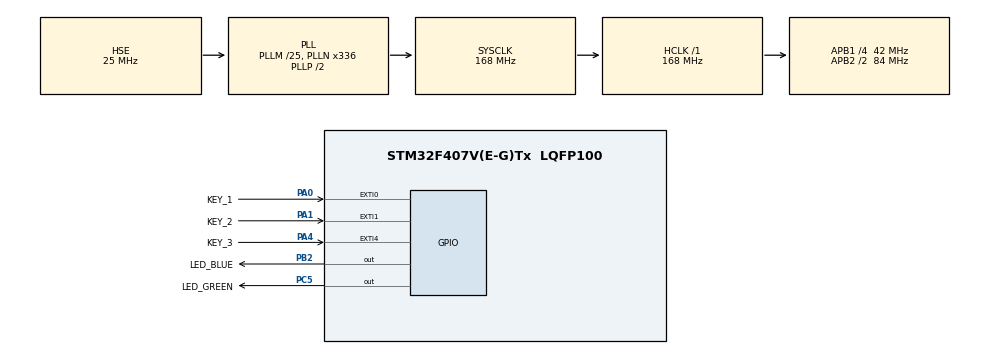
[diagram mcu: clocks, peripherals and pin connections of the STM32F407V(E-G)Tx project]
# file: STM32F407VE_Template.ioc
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Mcu.Family=STM32F4
Mcu.Name=STM32F407V(E-G)Tx
Mcu.Package=LQFP100
NVIC.EXTI0_IRQn=true\:0\:0\:false\:false\:true\:true\:true\:true
NVIC.EXTI1_IRQn=true\:0\:0\:false\:false\:true\:true\:true\:true
NVIC.EXTI4_IRQn=true\:0\:0\:false\:false\:true\:true\:true\:true
NVIC.PriorityGroup=NVIC_PRIORITYGROUP_4
PA0-WKUP.GPIO_Label=KEY_1
PA0-WKUP.GPIO_ModeDefaultEXTI=GPIO_MODE_IT_RISING
PA0-WKUP.GPIO_PuPd=GPIO_PULLDOWN
PA0-WKUP.Signal=GPXTI0
PA1.GPIO_Label=KEY_2
PA1.GPIO_ModeDefaultEXTI=GPIO_MODE_IT_FALLING
PA1.GPIO_PuPd=GPIO_PULLUP
PA1.Signal=GPXTI1
PA13.Mode=Serial_Wire
PA13.Signal=SYS_JTMS-SWDIO
PA14.Mode=Serial_Wire
PA14.Signal=SYS_JTCK-SWCLK
PA4.GPIO_Label=KEY_3
PA4.GPIO_ModeDefaultEXTI=GPIO_MODE_IT_FALLING
PA4.GPIO_PuPd=GPIO_PULLUP
PA4.Signal=GPXTI4
PB2.GPIO_Label=LED_BLUE
PB2.GPIO_PuPd=GPIO_PULLDOWN
PB2.Signal=GPIO_Output
PC5.GPIO_Label=LED_GREEN
PC5.GPIO_PuPd=GPIO_PULLDOWN
PC5.Signal=GPIO_Output
PH0-OSC_IN.Mode=HSE-External-Oscillator
PH0-OSC_IN.Signal=RCC_OSC_IN
PH1-OSC_OUT.Mode=HSE-External-Oscillator
PH1-OSC_OUT.Signal=RCC_OSC_OUT
ProjectManager.HeapSize=0x200
ProjectManager.StackSize=0x1000
ProjectManager.TargetToolchain=MDK-ARM V5.32
RCC.48MHZClocksFreq_Value=84000000
RCC.AHBFreq_Value=168000000
RCC.APB1CLKDivider=RCC_HCLK_DIV4
RCC.APB1Freq_Value=42000000
RCC.APB1TimFreq_Value=84000000
RCC.APB2CLKDivider=RCC_HCLK_DIV2
RCC.APB2Freq_Value=84000000
RCC.APB2TimFreq_Value=168000000
RCC.CortexFreq_Value=168000000
RCC.HCLKFreq_Value=168000000
RCC.HSE_VALUE=25000000
RCC.HSI_VALUE=16000000
RCC.LSE_VALUE=32768
RCC.PLLM=25
RCC.PLLN=336
RCC.PLLSourceVirtual=RCC_PLLSOURCE_HSE
RCC.SYSCLKFreq_VALUE=168000000
RCC.SYSCLKSource=RCC_SYSCLKSOURCE_PLLCLK
RCC.VCOOutputFreq_Value=336000000
board=custom

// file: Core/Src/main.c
/* USER CODE BEGIN Header */
/***********************************************************************************************************************************
 ** 【代码编写】  魔女开发板团队
 ** 【淘    宝】  魔女开发板       https://demoboard.taobao.com
 ***********************************************************************************************************************************
 ** 【实验名称】  STM32F407 GPIO —— 外部中断(EXTI)按键控制LED翻转
 **
 ** 【适用平台】  STM32F407 + keil5 + HAL库
 **
 ** 【 CubeMX 】  1- 开启外部高速晶振 HSE，系统时钟配置为 168MHz；
 **               2- PB2、PC5 配置为 GPIO 推挽输出（蓝灯、绿灯）；
 **               3- PA0、PA1、PA4 配置为外部中断模式（上升沿/下降沿触发）；
 **               4- PA0 下拉输入，PA1/PA4 上拉输入；
 **               5- 开启 EXTI 中断，并配置中断优先级；
 **
 ** 【功能说明】  本工程实现 GPIO 外部中断 + 按键控制：
 **               1- KEY1(PA0)、KEY2(PA1)、KEY3(PA4) 通过外部中断触发；
 **               2- 任意按键触发中断 → 翻转蓝灯(PB2)状态；
 **               3- 绿灯(PC5) 500ms 无阻塞闪烁，指示系统运行；
 **               4- 采用 HAL 中断回调函数，代码结构标准清晰；
 **
 ** 【代码使用】  1- 上电后绿灯自动闪烁；
 **               2- 按下任意按键 → 蓝灯立即翻转亮灭；
 **               3- 中断触发方式，不占用主循环资源；
 **
 ** 【划 重 点】  1- 外部中断回调函数固定名称：HAL_GPIO_EXTI_Callback；
 **               2- KEY1(PA0)：上升沿触发；KEY2/3(PA1/PA4)：下降沿触发；
 **               3- 中断方式响应速度更快，不阻塞主程序；
 **               4- 绿灯无阻塞闪烁：使用 HAL_GetTick() 计时；
 **               5- 所有用户代码必须写在 USER CODE 区间内；
 **
 *******************************************************************************/
/* USER CODE END Header */
#include "main.h"
#include "gpio.h"

void SystemClock_Config(void);

int main(void)
{
    /* USER CODE BEGIN 1 */

    /* 说明：
     * 1. 不要删除CubeMX生成的注释行（形如 USER CODE BEGIN/END），这些注释用于代码重新生成时的定位
     * 2. 所有用户自定义代码必须写在对应的BEGIN与END注释行之间，否则重新生成时会被覆盖
     * 3. 主要初始化函数说明：
     *    - HAL_Init()            初始化HAL库，配置中断优先级、系统时基等
     *    - SystemClock_Config()  配置系统时钟
     *    - MX_GPIO_Init()        初始化GPIO引脚（仅包含推挽输出、中断触发等配置）
     *    - 外设功能引脚（如UART、SPI等）的初始化在各自的功能文件中
     */

    /* USER CODE END 1 */

    /* MCU Configuration--------------------------------------------------------*/

    /* Reset of all peripherals, Initializes the Flash interface and the Systick. */
    HAL_Init();

    /* Configure the system clock */
    SystemClock_Config();

    /* Initialize all configured peripherals */
    MX_GPIO_Init();

    /* Infinite loop */
    while (1)
    {

        /* USER CODE BEGIN 3 */
        /* 所有用户代码，必须写在配对的BEGIN与END之间 */

        /** 1ms 延时 **/
        HAL_Delay(1 - 1);                                                  // 延时函数，参数：ms; 注意：CubeMX生成的HAL_Delay(), 函数内部为避免无效操作，会对传入参数+1，因此，如果只需要几ms延时建议传入参数时-1，如果需要大几百ms的非精准延时，那参数不-1也影响不大

        /** 每500ms执行一次的任务 **/
        static uint32_t lastTime_500ms = 0;                                // 定义静态变量，用于记录上次执行这个任务的时间点(单位：毫秒)
        if (HAL_GetTick() - lastTime_500ms >= 500)                         // 检查当前时间距离上次执行是否已经过了500毫秒; HAL_GetTick()是获取启动后经过的毫秒数
        {
            HAL_GPIO_TogglePin(LED_GREEN_GPIO_Port, LED_GREEN_Pin);        // 控制绿色LED引脚电平翻转(PC5); 规律地闪烁LED，方便外部观察系统是否正常运行
            lastTime_500ms =   HAL_GetTick();                              // 记录当前时间，作为新的基准点，为下一次判断做准备
        }

    }

    /* USER CODE END 3 */
}

void SystemClock_Config(void)
{
    RCC_OscInitTypeDef RCC_OscInitStruct = {0};
    RCC_ClkInitTypeDef RCC_ClkInitStruct = {0};

    /** Configure the main internal regulator output voltage
    */
    __HAL_RCC_PWR_CLK_ENABLE();
    __HAL_PWR_VOLTAGESCALING_CONFIG(PWR_REGULATOR_VOLTAGE_SCALE1);

    /** Initializes the RCC Oscillators according to the specified parameters
    * in the RCC_OscInitTypeDef structure.
    */
    RCC_OscInitStruct.OscillatorType = RCC_OSCILLATORTYPE_HSE;
    RCC_OscInitStruct.HSEState = RCC_HSE_ON;
    RCC_OscInitStruct.PLL.PLLState = RCC_PLL_ON;
    RCC_OscInitStruct.PLL.PLLSource = RCC_PLLSOURCE_HSE;
    RCC_OscInitStruct.PLL.PLLM = 25;
    RCC_OscInitStruct.PLL.PLLN = 336;
    RCC_OscInitStruct.PLL.PLLP = RCC_PLLP_DIV2;
    RCC_OscInitStruct.PLL.PLLQ = 4;
    if (HAL_RCC_OscConfig(&RCC_OscInitStruct) != HAL_OK)
    {
        Error_Handler();
    }

    /** Initializes the CPU, AHB and APB buses clocks
    */
    RCC_ClkInitStruct.ClockType = RCC_CLOCKTYPE_HCLK | RCC_CLOCKTYPE_SYSCLK
                                  | RCC_CLOCKTYPE_PCLK1 | RCC_CLOCKTYPE_PCLK2;
    RCC_ClkInitStruct.SYSCLKSource = RCC_SYSCLKSOURCE_PLLCLK;
    RCC_ClkInitStruct.AHBCLKDivider = RCC_SYSCLK_DIV1;
    RCC_ClkInitStruct.APB1CLKDivider = RCC_HCLK_DIV4;
    RCC_ClkInitStruct.APB2CLKDivider = RCC_HCLK_DIV2;

    if (HAL_RCC_ClockConfig(&RCC_ClkInitStruct, FLASH_LATENCY_5) != HAL_OK)
    {
        Error_Handler();
    }
}

/* USER CODE BEGIN 4 */
/* 所有用户代码，必须写在配对的BEGIN与END之间 */

/******************************************************************************
 * 函  数： HAL_GPIO_EXTI_Callback
 * 功  能： EXTI中断回调函数
 * 参  数： uint16_t  GPIO_Pin    引脚编号，参数范围：GPIO_Pin_0 ~ GPIO_Pin_15
 * 返回值： 无
 * 备  注： CubeMX生成的代码在思维和风格上，与使用标准库编写时有很大的区别。
 *          1：这个是回调函数，不是中断服务函数。完整的调用：EXTIx_IRQHandler() > HAL_GPIO_EXTI_IRQHandler(GPIO_PIN_x) > HAL_GPIO_EXTI_Callback(GPIO_PIN_x)
 *          2：必须使用这个函数名称，因为它在CubeMX生成时，已被写好了各种函数调用、函数弱定义(在stm32xx_hal_gpio.c的底部); 不建议在原弱定义中增添代码，而是重写本函数
 *          3：中断条件触发后，本函数被自动调用，无需进行人工调用; 也无需进行中断标志的清理，因为HAL_GPIO_EXTI_IRQHandler()函数中已有操作;
 *          4：生成的所有EXTI中断服务函数，都统一调用这个函数，以引脚编号作参数
 *          5：判断参数传进来的引脚编号，即可知道是哪个外部中断线产生的中断信号
******************************************************************************/
void HAL_GPIO_EXTI_Callback(uint16_t GPIO_Pin)
{
    if (1 == HAL_GPIO_ReadPin(GPIOA, GPIO_PIN_0))               // 按键1 产生的中断信号：KEY_1、PA0、闲时下拉、按下时高电平、上升沿触发
    {
        HAL_GPIO_TogglePin(GPIOB, GPIO_PIN_2);                  // 反转蓝色LED灯
    }

    if (0 == HAL_GPIO_ReadPin(GPIOA, GPIO_PIN_1))               // 按键2 产生的中断信号：KEY_2、PA1、闲时上拉、按下时低电平、下降沿触发
    {
        HAL_GPIO_TogglePin(GPIOB, GPIO_PIN_2);                  // 反转蓝色LED灯
    }

    if (0 == HAL_GPIO_ReadPin(GPIOA, GPIO_PIN_4))               // 按键3 产生的中断信号：KEY_3、PA4、闲时上拉、按下低高电平、下降沿触发
    {
        HAL_GPIO_TogglePin(GPIOB, GPIO_PIN_2);                  // 反转蓝色LED灯
    }

}

/* USER CODE END 4 */

void Error_Handler(void)
{
    __disable_irq();
    while (1)
    {
    }
}
